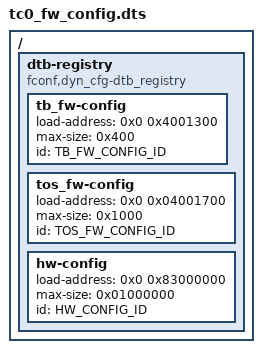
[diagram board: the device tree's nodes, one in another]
/*
 * Copyright (c) 2020, Arm Limited. All rights reserved.
 *
 * SPDX-License-Identifier: BSD-3-Clause
 */

#include <common/tbbr/tbbr_img_def.h>

/dts-v1/;

/ {
	dtb-registry {
		compatible = "fconf,dyn_cfg-dtb_registry";

		tb_fw-config {
			load-address = <0x0 0x4001300>;
			max-size = <0x400>;
			id = <TB_FW_CONFIG_ID>;
		};

		tos_fw-config {
			load-address = <0x0 0x04001700>;
			max-size = <0x1000>;
			id = <TOS_FW_CONFIG_ID>;
		};

		hw-config {
			load-address = <0x0 0x83000000>;
			max-size = <0x01000000>;
			id = <HW_CONFIG_ID>;
		};
	};
};
